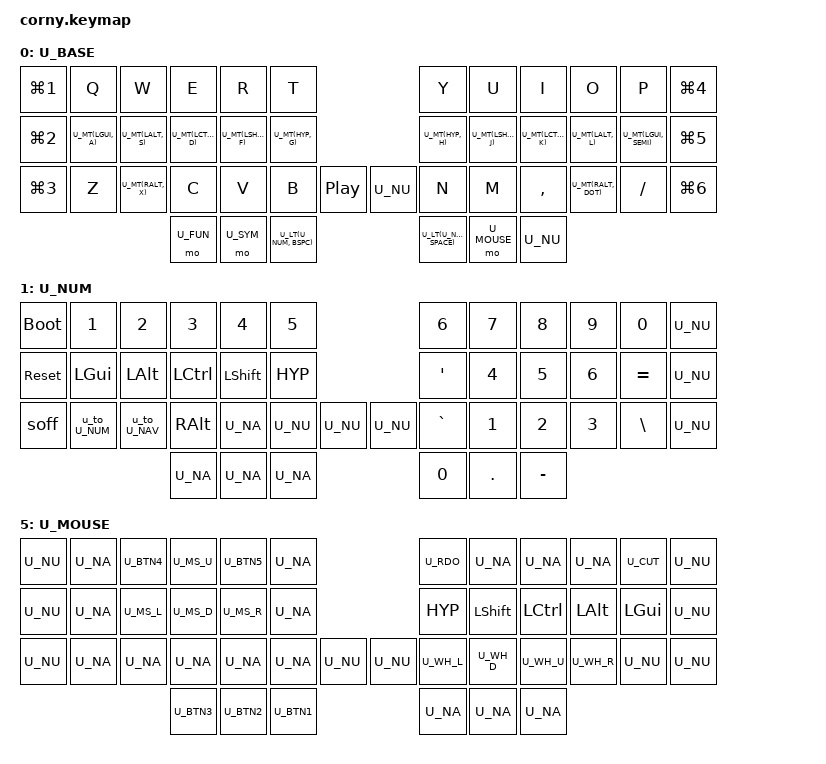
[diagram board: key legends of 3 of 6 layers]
#include <behaviors.dtsi>

#include <dt-bindings/zmk/keys.h>
#include <dt-bindings/zmk/bt.h>
#include <dt-bindings/zmk/rgb.h>
#include <dt-bindings/zmk/outputs.h>
#include <dt-bindings/zmk/pointing.h>
#include <dt-bindings/zmk/ext_power.h>

#include "../../../miryoku/constants.h"
#include "../../../miryoku/macros.dtsi"
#include "../../../miryoku/behaviors/behaviors.dtsi"
#include "../../../miryoku/layers/layers.h"
#include "../../../miryoku/combos/corne/combos.dtsi"
#include "../../../miryoku/mouse/mouse.h"

// ┌───┬───┬───┬───┬───┬───┐             ┌───┬───┬───┬───┬───┬───┐
// │   │   │   │   │   │   │┌→         ←┐│   │   │   │   │   │   │
// ├───┼───┼───┼───┼───┼───┤│┌───┐ ┌───┐│├───┼───┼───┼───┼───┼───┤
// │   │   │   │   │   │   │ │   │ │   │ │   │   │   │   │   │   │
// ├───┼───┼───┼───┼───┼───┤│└───┘ └───┘│├───┼───┼───┼───┼───┼───┤
// │   │   │   │   │   │   │└→         ←┘│   │   │   │   │   │   │
// └───┴───┴───┴──┬┴──┬┴──┬┴───┐     ┌───┴┬──┴┬──┴┬──┴───┴───┴───┘
//                │   │   │    │     │    │   │   │
//                └───┴───┴────┘     └────┴───┴───┘

#
/ {
    keymap {
        compatible = "zmk,keymap";

        // ┌───┬───┬───┬───┬───┬───┐             ┌───┬───┬───┬───┬───┬───┐
        // │AL1│ Q │ W │ E │ R │ T │┌→VOL+   ▲ ←┐│ Y │ U │ I │ O │ P │AL4│
        // ├───┼───┼───┼───┼───┼───┤│┌───┐ ┌───┐│├───┼───┼───┼───┼───┼───┤
        // │AL2│ A │ S │ D │ F │ G │ │CPP│ │   │ │ H │ J │ K │ L │ ; │AL5│
        // ├───┼───┼───┼───┼───┼───┤│└───┘ └───┘│├───┼───┼───┼───┼───┼───┤
        // │AL3│ Z │ X │ C │ V │ B │└→VOL-   ▼ ←┘│ N │ M │ , │ . │ / │AL6│
        // └───┴───┴───┴──┬┴──┬┴──┬┴───┐     ┌───┴┬──┴┬──┴┬──┴───┴───┴───┘
        //                │   │   │BKSP│     │SPCE│   │   │
        //                └───┴───┴────┘     └────┴───┴───┘
        U_BASE {
            bindings = <
                &kp LG(N1) &kp Q             &kp W         &kp E          &kp R          &kp T                           &kp Y              &kp U          &kp I          &kp O           &kp P                 &kp LG(N4)
                &kp LG(N2) U_MT(LGUI, A)     U_MT(LALT, S) U_MT(LCTRL, D) U_MT(LSHFT, F) U_MT(HYP, G)                    U_MT(HYP, H)       U_MT(LSHFT, J) U_MT(LCTRL, K) U_MT(LALT, L)   U_MT(LGUI, SEMI)      &kp LG(N5)
                &kp LG(N3) &kp Z         U_MT(RALT, X) &kp C          &kp V          &kp B             &kp C_PP U_NU &kp N              &kp M          &kp COMMA      U_MT(RALT, DOT)     &kp SLASH  &kp LG(N6)
                                                           &mo U_FUN      &mo U_SYM      U_LT(U_NUM, BSPC)               U_LT(U_NAV, SPACE) &mo U_MOUSE    U_NU
            >;
            sensor-bindings = <
                &inc_dec_kp C_VOL_UP C_VOL_DN &inc_dec_kp UP DOWN
            >;
        };

        // ┌───┬───┬───┬───┬───┬───┐             ┌───┬───┬───┬───┬───┬───┐
        // │BTL│ 1 │ 2 │ 3 │ 4 │ 5 │┌→VOL+   ◄ ←┐│ 6 │ 7 │ 8 │ 9 │ 0 │   │
        // ├───┼───┼───┼───┼───┼───┤│┌───┐ ┌───┐│├───┼───┼───┼───┼───┼───┤
        // │RST│GUI│ALT│CTL│SHT│HYP│ │   │ │   │ │ ' │ 4 │ 5 │ 6 │ = │   │
        // ├───┼───┼───┼───┼───┼───┤│└───┘ └───┘│├───┼───┼───┼───┼───┼───┤
        // │OFF│NUM│NAV│ALT│   │   │└→VOL-   ► ←┘│ ` │ 1 │ 2 │ 3 │ \ │   │
        // └───┴───┴───┴──┬┴──┬┴──┬┴───┐     ┌───┴┬──┴┬──┴┬──┴───┴───┴───┘
        //                │   │   │ [X]│     │  0 │ . │ - │
        //                └───┴───┴────┘     └────┴───┴───┘
        U_NUM {
            bindings = <
                &bootloader &kp N1       &kp N2        &kp N3      &kp N4    &kp N5               &kp N6    &kp N7  &kp N8  &kp N9    &kp N0    U_NU
                &sys_reset  &kp LGUI     &kp LALT      &kp LCTRL   &kp LSHFT &kp HYP              &kp SQT   &kp N4  &kp N5  &kp N6    &kp EQUAL U_NU
                &soff       &u_to_U_NUM  &u_to_U_NAV   &kp RALT    U_NA      U_NU    U_NU    U_NU &kp GRAVE &kp N1  &kp N2  &kp N3    &kp BSLH  U_NU
                                                       U_NA        U_NA      U_NA                 &kp N0    &kp DOT &kp MINUS
            >;
            sensor-bindings = <
                &inc_dec_kp C_VOL_UP C_VOL_DN &inc_dec_kp LEFT RIGHT
            >;
        };

        // ┌───┬───┬───┬───┬───┬───┐             ┌───┬───┬───┬───┬───┬───┐
        // │   │BSE│   │   │BUT│   │┌→VOL+   ▲ ←┐│ ^ │ & │ * │ ( │ ) │   │
        // ├───┼───┼───┼───┼───┼───┤│┌───┐ ┌───┐│├───┼───┼───┼───┼───┼───┤
        // │   │GUI│ALT│CTL│SHT│HYP│ │   │ │   │ │ " │ $ │ % │ ^ │ + │   │
        // ├───┼───┼───┼───┼───┼───┤│└───┘ └───┘│├───┼───┼───┼───┼───┼───┤
        // │   │SYM│MUS│ALT│   │   │└→VOL-   ▼ ←┘│ ~ │ ! │ @ │ # │ | │   │
        // └───┴───┴───┴──┬┴──┬┴──┬┴───┐     ┌───┴┬──┴┬──┴┬──┴───┴───┴───┘
        //                │   │[X]│    │     │  _ │ { │ } │
        //                └───┴───┴────┘     └────┴───┴───┘
        U_SYM {
            bindings = <
                U_NA &u_to_U_BASE U_NA          U_NA      U_BOOT    U_NU                 &kp CARET  &kp AMPS &kp ASTRK &kp LPAR  &kp RPAR U_NU
                U_NA &kp LGUI     &kp LALT      &kp LCTRL &kp LSHFT &kp HYP              &kp DQT   &kp DLLR &kp PRCNT &kp CARET &kp PLUS U_NU
                U_NA &u_to_U_SYM  &u_to_U_MOUSE &kp RALT  U_NA      U_NU    U_NU    U_NU &kp TILDE &kp EXCL &kp AT    &kp HASH  &kp PIPE U_NU
                                                U_NA      U_NA      U_NA                 &kp UNDER &kp LBRC &kp RBRC
            >;
            sensor-bindings = <
                &inc_dec_kp C_VOL_UP C_VOL_DN &inc_dec_kp UP DOWN
            >;
        };

        // ┌───┬───┬───┬───┬───┬───┐             ┌───┬───┬───┬───┬───┬───┐
        // │   │OUT│   │   │BSE│   │┌→BRT+   ▲ ←┐│BT0│BT1│BT2│BT3│BT4│BTL│
        // ├───┼───┼───┼───┼───┼───┤│┌───┐ ┌───┐│├───┼───┼───┼───┼───┼───┤
        // │   │GUI│ALT│CTL│SHT│HYP│ │ABR│ │   │ │ ◄ │ ▼ │ ▲ │ ► │CAP│RST│
        // ├───┼───┼───┼───┼───┼───┤│└───┘ └───┘│├───┼───┼───┼───┼───┼───┤
        // │   │FUN│ALT│NUM│NAV│   │└→BRT-   ▼ ←┘│HOM│PGD│PGU│END│INS│OFF│
        // └───┴───┴───┴──┬┴──┬┴──┬┴───┐     ┌───┴┬──┴┬──┴┬──┴───┴───┴───┘
        //                │   │   │ DEL│     │ [X]│   │   │
        //                └───┴───┴────┘     └────┴───┴───┘
        U_NAV {
            bindings = <
                U_NU &u_out_tog  U_NA     U_NA        &u_to_U_BASE U_NA                           &u_bt_sel_0 &u_bt_sel_1 &u_bt_sel_2 &u_bt_sel_3 &u_bt_sel_4  &bootloader
                U_NU &kp LGUI    &kp LALT &kp LCTRL   &kp LSHFT    &kp HYP                        &kp LEFT    &kp DOWN    &kp UP      &kp RIGHT   &u_caps_word &sys_reset
                U_NU &u_to_U_FUN &kp RALT &u_to_U_NUM &u_to_U_NAV  U_NA    &kp C_BRI_AUTO    U_NA &kp HOME    &kp PG_DN   &kp PG_UP   &kp END     &kp INS      &soff
                                          U_NA        U_NA         &kp DEL                        &kp RET     &kp SPACE   &kp DEL
            >;
            sensor-bindings = <
                &inc_dec_kp C_BRI_UP C_BRI_DN &inc_dec_kp UP DOWN
            >;
        };

        // ┌───┬───┬───┬───┬───┬───┐             ┌───┬───┬───┬───┬───┬───┐
        // │   │BSE│   │   │BUT│   │┌→VOL+ PGUP←┐│PSR│ F7│ F8│ F9│F10│   │
        // ├───┼───┼───┼───┼───┼───┤│┌───┐ ┌───┐│├───┼───┼───┼───┼───┼───┤
        // │   │GUI│ALT│CTL│SHT│HYP│ │   │ │   │ │SLC│ F4│ F5│ F6│F11│   │
        // ├───┼───┼───┼───┼───┼───┤│└───┘ └───┘│├───┼───┼───┼───┼───┼───┤
        // │   │FUN│   │ALT│   │   │└→VOL- PGDN←┘│ PB│ F1│ F2│ F3│F12│   │
        // └───┴───┴───┴──┬┴──┬┴──┬┴───┐     ┌───┴┬──┴┬──┴┬──┴───┴───┴───┘
        //                │[X]│   │ DEL│     │KAPP│SPC│BSP│
        //                └───┴───┴────┘     └────┴───┴───┘
        U_FUN {
            bindings = <
                U_NU &u_to_U_BASE U_NA     U_NA      U_BOOT    U_NU                 &kp PSCRN       &kp F7    &kp F8    &kp F9    &kp F10 U_NA
                U_NU &kp LGUI     &kp LALT &kp LCTRL &kp LSHFT &kp HYP              &kp SLCK        &kp F4    &kp F5    &kp F6    &kp F11 U_NA
                U_NU &u_to_U_FUN  U_NA     &kp RALT  U_NA      U_NU    U_NU    U_NU &kp PAUSE_BREAK &kp F1    &kp F2    &kp F3    &kp F12 U_NA
                                           U_NA      U_NA      U_NA                 &kp K_APP       &kp SPACE &kp BSPC
            >;
            sensor-bindings = <
                &inc_dec_kp C_VOL_UP C_VOL_DN &inc_dec_kp PG_UP PG_DN
            >;
        };

        // ┌───┬───┬───┬───┬───┬───┐             ┌───┬───┬───┬───┬───┬───┐
        // │   │   │MB4│MMU│MM5│   │┌→VOL+ PGUP←┐│RDO│   │   │   │CUT│   │
        // ├───┼───┼───┼───┼───┼───┤│┌───┐ ┌───┐│├───┼───┼───┼───┼───┼───┤
        // │   │   │MML│MMD│MMR│   │ │   │ │   │ │HYP│SHT│CTL│ALT│GUI│   │
        // ├───┼───┼───┼───┼───┼───┤│└───┘ └───┘│├───┼───┼───┼───┼───┼───┤
        // │   │   │   │   │   │   │└→VOL- PGDN←┘│MWL│MWD│MWU│MWR│   │   │
        // └───┴───┴───┴──┬┴──┬┴──┬┴───┐     ┌───┴┬──┴┬──┴┬──┴───┴───┴───┘
        //                │MBM│MBR│ MBL│     │    │[X]│   │
        //                └───┴───┴────┘     └────┴───┴───┘
        U_MOUSE {
            bindings = <
                U_NU U_NA U_BTN4 U_MS_U U_BTN5 U_NA             U_RDO   U_NA      U_NA       U_NA      U_CUT    U_NU
                U_NU U_NA U_MS_L U_MS_D U_MS_R U_NA             &kp HYP &kp LSHFT &kp LCTRL  &kp LALT  &kp LGUI U_NU
                U_NU U_NA U_NA   U_NA   U_NA   U_NA   U_NU U_NU U_WH_L  U_WH_D    U_WH_U     U_WH_R    U_NU     U_NU
                                 U_BTN3 U_BTN2 U_BTN1           U_NA    U_NA      U_NA
            >;
            sensor-bindings = <
                &inc_dec_kp C_VOL_UP C_VOL_DN &inc_dec_kp PG_UP PG_DN
            >;
        };
    };
};
